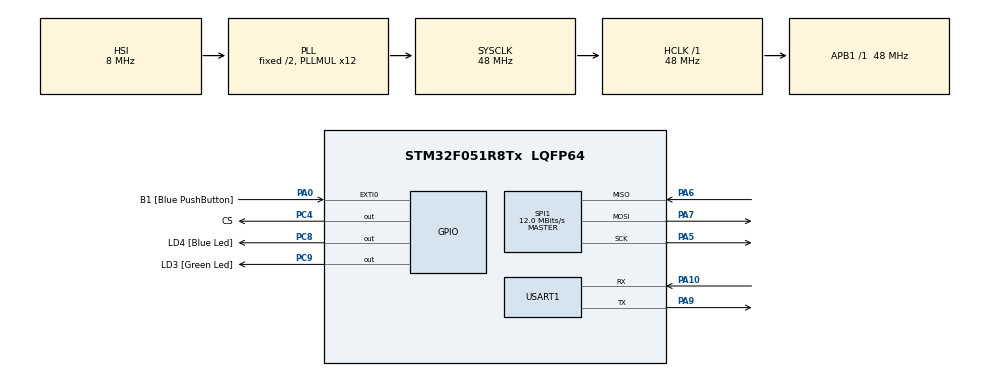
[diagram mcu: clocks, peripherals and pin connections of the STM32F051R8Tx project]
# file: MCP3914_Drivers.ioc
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Mcu.Family=STM32F0
Mcu.Name=STM32F051R8Tx
Mcu.Package=LQFP64
PA0.GPIO_Label=B1 [Blue PushButton]
PA0.GPIO_ModeDefaultEXTI=GPIO_MODE_EVT_RISING
PA0.Signal=GPXTI0
PA10.Mode=Asynchronous
PA10.Signal=USART1_RX
PA13.GPIO_Label=SWDIO
PA13.Mode=Serial_Wire
PA13.Signal=SYS_SWDIO
PA14.GPIO_Label=SWCLK
PA14.Mode=Serial_Wire
PA14.Signal=SYS_SWCLK
PA5.Mode=Full_Duplex_Master
PA5.Signal=SPI1_SCK
PA6.Mode=Full_Duplex_Master
PA6.Signal=SPI1_MISO
PA7.Mode=Full_Duplex_Master
PA7.Signal=SPI1_MOSI
PA9.Mode=Asynchronous
PA9.Signal=USART1_TX
PC4.GPIO_Label=CS
PC4.Signal=GPIO_Output
PC8.GPIO_Label=LD4 [Blue Led]
PC8.Signal=GPIO_Output
PC9.GPIO_Label=LD3 [Green Led]
PC9.Signal=GPIO_Output
ProjectManager.HeapSize=0x200
ProjectManager.StackSize=0x400
ProjectManager.TargetToolchain=Makefile
RCC.AHBFreq_Value=48000000
RCC.APB1Freq_Value=48000000
RCC.APB1TimFreq_Value=48000000
RCC.HCLKFreq_Value=48000000
RCC.PLLMUL=RCC_PLL_MUL12
RCC.SYSCLKFreq_VALUE=48000000
RCC.SYSCLKSource=RCC_SYSCLKSOURCE_PLLCLK
SPI1.BaudRatePrescaler=SPI_BAUDRATEPRESCALER_4
SPI1.CalculateBaudRate=12.0 MBits/s
SPI1.DataSize=SPI_DATASIZE_8BIT
SPI1.Direction=SPI_DIRECTION_2LINES
SPI1.Mode=SPI_MODE_MASTER
SPI1.VirtualType=VM_MASTER
USART1.VirtualMode-Asynchronous=VM_ASYNC
board=STM32F0DISCOVERY

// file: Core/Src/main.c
/* USER CODE BEGIN Header */
/**
  ******************************************************************************
  * @file           : main.c
  * @brief          : Main program body
  ******************************************************************************
  * @attention
  *
  * Copyright (c) 2024 STMicroelectronics.
  * All rights reserved.
  *
  * This software is licensed under terms that can be found in the LICENSE file
  * in the root directory of this software component.
  * If no LICENSE file comes with this software, it is provided AS-IS.
  *
  ******************************************************************************
  */
/* USER CODE END Header */
#include "main.h"

/* USER CODE BEGIN Includes */
#include "MCP3914.h"
/* USER CODE END Includes */

SPI_HandleTypeDef hspi1;

UART_HandleTypeDef huart1;

/* USER CODE BEGIN PV */
MCP3914 adc;
/* USER CODE END PV */

void SystemClock_Config(void);
static void MX_GPIO_Init(void);
static void MX_SPI1_Init(void);
static void MX_USART1_UART_Init(void);

int main(void)
{

  /* MCU Configuration--------------------------------------------------------*/

  /* Reset of all peripherals, Initializes the Flash interface and the Systick. */
  HAL_Init();

  /* Configure the system clock */
  SystemClock_Config();

  /* Initialize all configured peripherals */
  MX_GPIO_Init();
  MX_SPI1_Init();
  MX_USART1_UART_Init();
  MCP3914_Initialise(&adc, &hspi1, CS_GPIO_Port, CS_Pin);
  /* Infinite loop */
  /* USER CODE BEGIN WHILE */
  while (1)
  {
    MCP3914_ReadRegister(&adc, MCP3914_REG_CHANNEL_2);
    char buffer[16];
    sprintf(buffer, "%02X%02X%02X\r\n",adc.adcData[0], adc.adcData[1], adc.adcData[2]);
    HAL_UART_Transmit(&huart1, (uint8_t*)buffer, strlen(buffer), HAL_MAX_DELAY);

    HAL_Delay(1000);

    /* USER CODE END WHILE */
  }
}

void SystemClock_Config(void)
{
  RCC_OscInitTypeDef RCC_OscInitStruct = {0};
  RCC_ClkInitTypeDef RCC_ClkInitStruct = {0};
  RCC_PeriphCLKInitTypeDef PeriphClkInit = {0};

  /** Initializes the RCC Oscillators according to the specified parameters
  * in the RCC_OscInitTypeDef structure.
  */
  RCC_OscInitStruct.OscillatorType = RCC_OSCILLATORTYPE_HSI;
  RCC_OscInitStruct.HSIState = RCC_HSI_ON;
  RCC_OscInitStruct.HSICalibrationValue = RCC_HSICALIBRATION_DEFAULT;
  RCC_OscInitStruct.PLL.PLLState = RCC_PLL_ON;
  RCC_OscInitStruct.PLL.PLLSource = RCC_PLLSOURCE_HSI;
  RCC_OscInitStruct.PLL.PLLMUL = RCC_PLL_MUL12;
  RCC_OscInitStruct.PLL.PREDIV = RCC_PREDIV_DIV1;
  if (HAL_RCC_OscConfig(&RCC_OscInitStruct) != HAL_OK)
  {
    Error_Handler();
  }

  /** Initializes the CPU, AHB and APB buses clocks
  */
  RCC_ClkInitStruct.ClockType = RCC_CLOCKTYPE_HCLK|RCC_CLOCKTYPE_SYSCLK
                              |RCC_CLOCKTYPE_PCLK1;
  RCC_ClkInitStruct.SYSCLKSource = RCC_SYSCLKSOURCE_PLLCLK;
  RCC_ClkInitStruct.AHBCLKDivider = RCC_SYSCLK_DIV1;
  RCC_ClkInitStruct.APB1CLKDivider = RCC_HCLK_DIV1;

  if (HAL_RCC_ClockConfig(&RCC_ClkInitStruct, FLASH_LATENCY_1) != HAL_OK)
  {
    Error_Handler();
  }
  PeriphClkInit.PeriphClockSelection = RCC_PERIPHCLK_USART1;
  PeriphClkInit.Usart1ClockSelection = RCC_USART1CLKSOURCE_PCLK1;
  if (HAL_RCCEx_PeriphCLKConfig(&PeriphClkInit) != HAL_OK)
  {
    Error_Handler();
  }
}

static void MX_SPI1_Init(void)
{

  /* SPI1 parameter configuration*/
  hspi1.Instance = SPI1;
  hspi1.Init.Mode = SPI_MODE_MASTER;
  hspi1.Init.Direction = SPI_DIRECTION_2LINES;
  hspi1.Init.DataSize = SPI_DATASIZE_8BIT;
  hspi1.Init.CLKPolarity = SPI_POLARITY_LOW;
  hspi1.Init.CLKPhase = SPI_PHASE_1EDGE;
  hspi1.Init.NSS = SPI_NSS_SOFT;
  hspi1.Init.BaudRatePrescaler = SPI_BAUDRATEPRESCALER_4;
  hspi1.Init.FirstBit = SPI_FIRSTBIT_MSB;
  hspi1.Init.TIMode = SPI_TIMODE_DISABLE;
  hspi1.Init.CRCCalculation = SPI_CRCCALCULATION_DISABLE;
  hspi1.Init.CRCPolynomial = 7;
  hspi1.Init.CRCLength = SPI_CRC_LENGTH_DATASIZE;
  hspi1.Init.NSSPMode = SPI_NSS_PULSE_ENABLE;
  if (HAL_SPI_Init(&hspi1) != HAL_OK)
  {
    Error_Handler();
  }

}

static void MX_USART1_UART_Init(void)
{

  huart1.Instance = USART1;
  huart1.Init.BaudRate = 38400;
  huart1.Init.WordLength = UART_WORDLENGTH_8B;
  huart1.Init.StopBits = UART_STOPBITS_1;
  huart1.Init.Parity = UART_PARITY_NONE;
  huart1.Init.Mode = UART_MODE_TX_RX;
  huart1.Init.HwFlowCtl = UART_HWCONTROL_NONE;
  huart1.Init.OverSampling = UART_OVERSAMPLING_16;
  huart1.Init.OneBitSampling = UART_ONE_BIT_SAMPLE_DISABLE;
  huart1.AdvancedInit.AdvFeatureInit = UART_ADVFEATURE_NO_INIT;
  if (HAL_UART_Init(&huart1) != HAL_OK)
  {
    Error_Handler();
  }

}

static void MX_GPIO_Init(void)
{
  GPIO_InitTypeDef GPIO_InitStruct = {0};

  /* GPIO Ports Clock Enable */
  __HAL_RCC_GPIOA_CLK_ENABLE();
  __HAL_RCC_GPIOC_CLK_ENABLE();

  /*Configure GPIO pin Output Level */
  HAL_GPIO_WritePin(GPIOC, CS_Pin|LD4_Pin|LD3_Pin, GPIO_PIN_RESET);

  /*Configure GPIO pin : B1_Pin */
  GPIO_InitStruct.Pin = B1_Pin;
  GPIO_InitStruct.Mode = GPIO_MODE_EVT_RISING;
  GPIO_InitStruct.Pull = GPIO_NOPULL;
  HAL_GPIO_Init(B1_GPIO_Port, &GPIO_InitStruct);

  /*Configure GPIO pins : CS_Pin LD4_Pin LD3_Pin */
  GPIO_InitStruct.Pin = CS_Pin|LD4_Pin|LD3_Pin;
  GPIO_InitStruct.Mode = GPIO_MODE_OUTPUT_PP;
  GPIO_InitStruct.Pull = GPIO_NOPULL;
  GPIO_InitStruct.Speed = GPIO_SPEED_FREQ_LOW;
  HAL_GPIO_Init(GPIOC, &GPIO_InitStruct);

}

void Error_Handler(void)
{
  __disable_irq();
  while (1)
  {
  }
}
